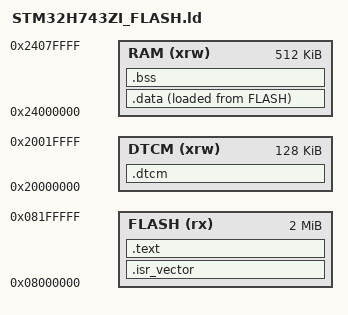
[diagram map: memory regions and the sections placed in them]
/* Minimal STM32H743ZI linker script for local build verification.
 * Memory layout follows RM0433: 2 MB internal flash at 0x08000000,
 * 512 KB AXI SRAM at 0x24000000, 128 KB DTCM at 0x20000000.
 */
ENTRY(Reset_Handler)

MEMORY
{
    FLASH (rx)  : ORIGIN = 0x08000000, LENGTH = 2048K
    RAM   (xrw) : ORIGIN = 0x24000000, LENGTH = 512K
    DTCM  (xrw) : ORIGIN = 0x20000000, LENGTH = 128K
}

_estack = ORIGIN(RAM) + LENGTH(RAM);

SECTIONS
{
    .isr_vector :
    {
        . = ALIGN(4);
        KEEP(*(.isr_vector))
        . = ALIGN(4);
    } > FLASH

    .text :
    {
        . = ALIGN(4);
        *(.text)
        *(.text*)
        *(.rodata)
        *(.rodata*)
        . = ALIGN(4);
    } > FLASH

    _sidata = LOADADDR(.data);

    .data :
    {
        . = ALIGN(4);
        _sdata = .;
        *(.data)
        *(.data*)
        . = ALIGN(4);
        _edata = .;
    } > RAM AT> FLASH

    .bss :
    {
        . = ALIGN(4);
        _sbss = .;
        *(.bss)
        *(.bss*)
        *(COMMON)
        . = ALIGN(4);
        _ebss = .;
    } > RAM

    .dtcm (NOLOAD) :
    {
        . = ALIGN(4);
        *(.dtcm)
        *(.dtcm*)
        . = ALIGN(4);
    } > DTCM

    /DISCARD/ :
    {
        *(.ARM.exidx*)
        *(.ARM.extab*)
    }
}
